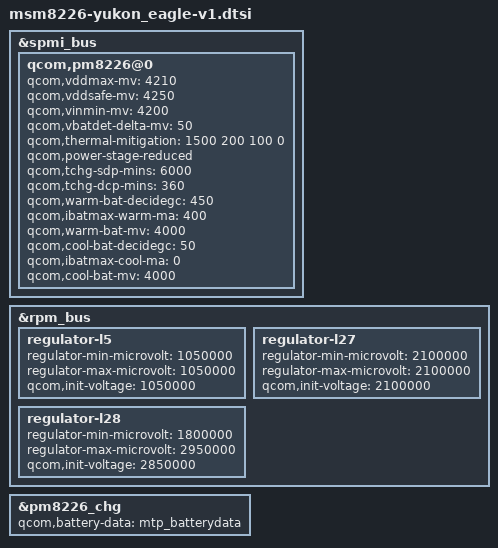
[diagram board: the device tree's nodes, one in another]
&spmi_bus {
	qcom,pm8226@0 {
		qcom,vddmax-mv = <4210>;
		qcom,vddsafe-mv = <4250>;
		qcom,vinmin-mv = <4200>;
		qcom,vbatdet-delta-mv = <50>;
		qcom,thermal-mitigation = <1500 200 100 0>;
		qcom,power-stage-reduced;
		qcom,tchg-sdp-mins = <6000>;
		qcom,tchg-dcp-mins = <360>;
		qcom,warm-bat-decidegc = <450>;
		qcom,ibatmax-warm-ma = <400>;
		qcom,warm-bat-mv = <4000>;
		qcom,cool-bat-decidegc = <50>;
		qcom,ibatmax-cool-ma = <0>;
		qcom,cool-bat-mv = <4000>;
	};
};

&rpm_bus {
	regulator-l5 {
		regulator-min-microvolt = <1050000>;
		regulator-max-microvolt = <1050000>;
		qcom,init-voltage = <1050000>;
	};
	regulator-l27 {
		regulator-min-microvolt = <2100000>;
		regulator-max-microvolt = <2100000>;
		qcom,init-voltage = <2100000>;
	};
	regulator-l28 {
		regulator-min-microvolt = <1800000>;
		regulator-max-microvolt = <2950000>;
		qcom,init-voltage = <2850000>;
	};
};

&pm8226_chg {
	qcom,battery-data = <&mtp_batterydata>;
};

/include/ "msm8226-yukon_eagle-720p-mtp.dtsi"
